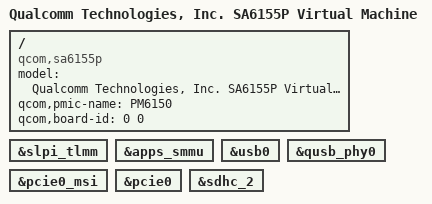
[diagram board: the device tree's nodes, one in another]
/*
 * Copyright (c) 2019, The Linux Foundation. All rights reserved.

 * This program is free software; you can redistribute it and/or modify
 * it under the terms of the GNU General Public License version 2 and
 * only version 2 as published by the Free Software Foundation.

 * This program is distributed in the hope that it will be useful,
 * but WITHOUT ANY WARRANTY; without even the implied warranty of
 * MERCHANTABILITY or FITNESS FOR A PARTICULAR PURPOSE.  See the
 * GNU General Public License for more details.
 */

/dts-v1/;

#include "sa6155p-vm.dtsi"

/ {
	model = "Qualcomm Technologies, Inc. SA6155P Virtual Machine";
	compatible = "qcom,sa6155p";
	qcom,pmic-name = "PM6150";
	qcom,board-id = <0 0>;
};

&slpi_tlmm {
	status = "ok";
};

&apps_smmu {
	status = "ok";
};

&usb0 {
	status = "ok";
};

&qusb_phy0 {
	status = "ok";
};

&pcie0_msi {
	status = "ok";
};

&pcie0 {
	status = "ok";
};

&sdhc_2 {
	status = "ok";
};

